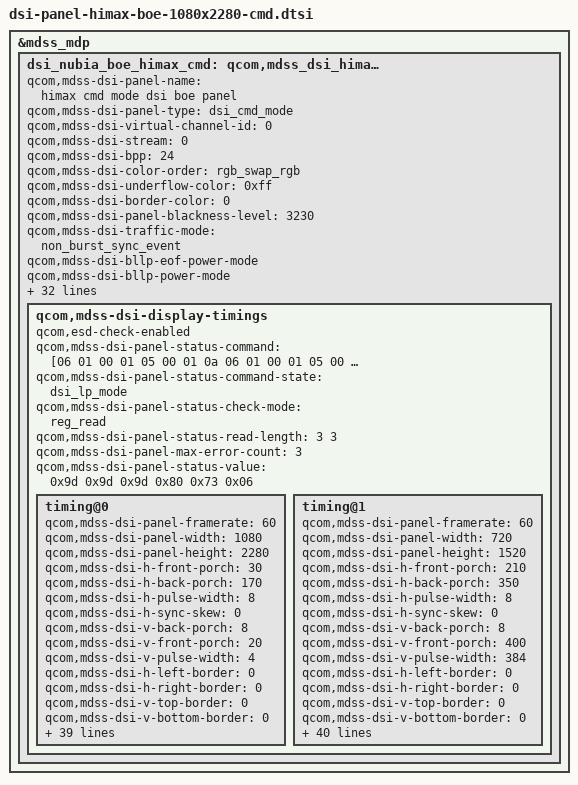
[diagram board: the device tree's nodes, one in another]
/* Copyright (c) 2016-2017, The Linux Foundation. All rights reserved.
 *
 * This program is free software; you can redistribute it and/or modify
 * it under the terms of the GNU General Public License version 2 and
 * only version 2 as published by the Free Software Foundation.
 *
 * This program is distributed in the hope that it will be useful,
 * but WITHOUT ANY WARRANTY; without even the implied warranty of
 * MERCHANTABILITY or FITNESS FOR A PARTICULAR PURPOSE.  See the
 * GNU General Public License for more details.
 */
&mdss_mdp {
	dsi_nubia_boe_himax_cmd: qcom,mdss_dsi_himax_cmd_boe {
		qcom,mdss-dsi-panel-name =
			"himax cmd mode dsi boe panel";
		qcom,mdss-dsi-panel-type = "dsi_cmd_mode";
		qcom,mdss-dsi-virtual-channel-id = <0>;
		qcom,mdss-dsi-stream = <0>;
		qcom,mdss-dsi-bpp = <24>;
		qcom,mdss-dsi-color-order = "rgb_swap_rgb";
		qcom,mdss-dsi-underflow-color = <0xff>;
		qcom,mdss-dsi-border-color = <0>;
		qcom,mdss-dsi-panel-blackness-level = <3230>;
		qcom,mdss-dsi-traffic-mode = "non_burst_sync_event";
		qcom,mdss-dsi-bllp-eof-power-mode;
		qcom,mdss-dsi-bllp-power-mode;
		qcom,mdss-dsi-lane-0-state;
		qcom,mdss-dsi-lane-1-state;
		qcom,mdss-dsi-lane-2-state;
		qcom,mdss-dsi-lane-3-state;
		qcom,mdss-dsi-dma-trigger = "trigger_sw";
		qcom,mdss-dsi-mdp-trigger = "none";
		qcom,mdss-dsi-reset-sequence =<1 2>, <0 2>, <1 60>;
		qcom,adjust-timer-wakeup-ms = <1>;
		qcom,mdss-dsi-te-pin-select = <1>;
		qcom,mdss-dsi-wr-mem-start = <0x2c>;
		qcom,mdss-dsi-wr-mem-continue = <0x3c>;
		qcom,mdss-dsi-te-dcs-command = <1>;
		qcom,mdss-dsi-te-check-enable;
		qcom,mdss-dsi-te-using-te-pin;
        qcom,mdss-dsi-t-clk-post = <0x0f>;
        qcom,mdss-dsi-t-clk-pre = <0x36>;
/**************************ESD check*******************************/
		qcom,esd-check-enabled;
		qcom,mdss-dsi-panel-status-command = [06 01 00 01 05 00 01 0a
												06 01 00 01 05 00 01 09];
		//qcom,mdss-dsi-panel-status-command = [14 01 00 01 05 00 01 0A];
		qcom,mdss-dsi-panel-status-command-state = "dsi_lp_mode";
		qcom,mdss-dsi-panel-status-check-mode = "reg_read";
		qcom,mdss-dsi-panel-status-read-length = <3 3>;
		qcom,mdss-dsi-panel-max-error-count = <3>;
		qcom,mdss-dsi-panel-status-value = <0x9d 0x9d 0x9d 0x80 0x73 0x06>;
/*********************************************************/
/************************switch panel mode*****************************/
               qcom,dynamic-mode-switch-enabled;
               qcom,dynamic-mode-switch-type="dynamic-resolution-switch-immediate";
              qcom,mdss-dsi-timing-switch-command-state="dsi_lp_mode";
/*****************************************************/
		qcom,mdss-dsi-display-timings {
/**************************ESD check*******************************/
		qcom,esd-check-enabled;
		qcom,mdss-dsi-panel-status-command = [06 01 00 01 05 00 01 0a
												06 01 00 01 05 00 01 09];
		//qcom,mdss-dsi-panel-status-command = [14 01 00 01 05 00 01 0A];
		qcom,mdss-dsi-panel-status-command-state = "dsi_lp_mode";
		qcom,mdss-dsi-panel-status-check-mode = "reg_read";
		qcom,mdss-dsi-panel-status-read-length = <3 3>;
		qcom,mdss-dsi-panel-max-error-count = <3>;
		qcom,mdss-dsi-panel-status-value = <0x9d 0x9d 0x9d 0x80 0x73 0x06>;
/*********************************************************/
			timing@0{
				qcom,mdss-dsi-panel-framerate = <60>;
				qcom,mdss-dsi-panel-width = <1080>;
				qcom,mdss-dsi-panel-height = <2280>;
				qcom,mdss-dsi-h-front-porch = <30>;
				qcom,mdss-dsi-h-back-porch = <170>;
				qcom,mdss-dsi-h-pulse-width = <8>;
				qcom,mdss-dsi-h-sync-skew = <0>;
				qcom,mdss-dsi-v-back-porch = <8>;
				qcom,mdss-dsi-v-front-porch = <20>;
				qcom,mdss-dsi-v-pulse-width = <4>;
				qcom,mdss-dsi-h-left-border = <0>;
				qcom,mdss-dsi-h-right-border = <0>;
				qcom,mdss-dsi-v-top-border = <0>;
				qcom,mdss-dsi-v-bottom-border = <0>;
				qcom,mdss-dsi-panel-jitter = <0x2 0xa>;
				qcom,mdss-dsi-on-command= [
					39 00 00 00 00 00 03 51 0f ff
					39 01 00 00 00 00 02 53 24
					05 01 00 00 00 00 01 35					
					39 00 00 00 00 00 04 B9 83 11 2E
					39 00 00 00 00 00 02 BD 00
					39 00 00 00 00 00 02 E3 09
					05 01 00 00 50 00 01 11 
					05 01 00 00 05 00 01 29 ];
				qcom,mdss-dsi-off-command = [
				05 01 00 00 28 00 01 28
				05 01 00 00 78 00 01 10];
                qcom,mdss-dsi-panel-phy-timings = [00 24 09 09 26 24 09 09 06 02 04 00];
                qcom,display-topology = <1 0 1>;
                qcom,default-topology-index = <0>;
				qcom,mdss-dsi-on-command-state = "dsi_lp_mode";
				qcom,mdss-dsi-off-command-state = "dsi_hs_mode";
				qcom,mdss-dsi-h-sync-pulse = <0>;
				qcom,mdss-dsi-lp11-init;
				qcom,mdss-dsi-init-delay-us=<30000>;
				qcom,mdss-dsi-timing-switch-command=[
					39 00 00 00 00 00 03 51 0f ff
					39 01 00 00 00 00 02 53 24
					05 01 00 00 00 00 01 35 
					39 00 00 00 00 00 04 B9 83 11 2E
					39 00 00 00 00 00 02 BD 00
					39 00 00 00 00 00 02 E3 09
					05 01 00 00 50 00 01 11 
					05 01 00 00 05 00 01 29 ];
/**************************ESD check*******************************/
		qcom,esd-check-enabled;
		qcom,mdss-dsi-panel-status-command = [06 01 00 01 05 00 01 0a
		                                      06 01 00 01 05 00 01 09];
		//qcom,mdss-dsi-panel-status-command = [14 01 00 01 05 00 01 0A];
		qcom,mdss-dsi-panel-status-command-state = "dsi_lp_mode";
		qcom,mdss-dsi-panel-status-check-mode = "reg_read";
		qcom,mdss-dsi-panel-status-read-length = <3 3>;
		qcom,mdss-dsi-panel-max-error-count = <3>;
		qcom,mdss-dsi-panel-status-value = <0x9d 0x9d 0x9d 0x80 0x73 0x06>;
/*********************************************************/
/*****************************************CABC setup start******************************/
/*					nuiba,mdss-dsi-cabc-command-cabc-off = [
											39 00 00 00 00 00 02 53 24
											39 01 00 00 00 00 02 55 00];
					nuiba,mdss-dsi-cabc-command-cabc-level1 = [
											39 00 00 00 00 00 02 53 2c
						        39 01 00 00 00 00 02 55 01];
			       		nuiba,mdss-dsi-cabc-command-cabc-off-state = "dsi_hs_mode";
					nuiba,mdss-dsi-cabc-command-cabc-level1-state = "dsi_hs_mode";
*/
/*****************************************CABC setup end******************************/
/**************************rgbw mode switch start *********************************************/
					nuiba,mdss-dsi-prim-panel-command-rgbw-normal = [
						39 00 00 00 00 00 02 53 2c
						39 00 00 00 00 00 02 55 01
						39 00 00 00 00 00 04 B9 83 11 2E
						39 00 00 00 00 00 02 BD 01
						39 00 00 00 00 00 02 C4 FF
						39 00 00 00 00 00 02 BD 02
						39 00 00 00 00 00 1B DF 87 0E 00 00 1F 95 D6 A2 82 22 01 00 00 00 00 00 40 2E 40 2E 40 40 2E 40 2E 01
						39 00 00 00 00 00 02 BD 03
						39 00 00 00 00 00 32 DF 20 20 20 7F 7F 20 B4 3D 2D B1 A5 92 C0 0C 00 7F 00 7F 00 00 00 00 10 7E 7D 08 7F 82 6C 0B 50 04 96 0C 00 80 00 00 96 70 14 00 00 3C 00 70 05 40 04
						39 00 00 00 00 00 02 BD 00
						39 00 00 00 00 00 02 E3 09
						39 01 00 00 00 00 15 EF 7F 02 7F 7F 02 00 00 80 80 FC 5E FD 75 00 FE 80 FF 80 40 E2
						/**below for read & wirte**/
						39 00 00 00 00 00 02 BD 01
						39 00 00 00 00 00 02 C4 00
						39 01 00 00 00 00 02 BD 00
					];
					nuiba,mdss-dsi-prim-panel-command-rgbw-bright = [
						39 00 00 00 00 00 02 53 2c
						39 00 00 00 00 00 02 55 01
						39 00 00 00 00 00 04 B9 83 11 2E
						39 00 00 00 00 00 02 BD 01
						39 00 00 00 00 00 02 C4 FF
						39 00 00 00 00 00 02 BD 02
						39 00 00 00 00 00 1B DF 87 0E 0A 00 1F 95 D6 A2 82 22 41 00 00 00 00 00 40 2E 40 2E 40 40 2E 40 2E 00
						39 00 00 00 00 00 02 BD 03
						39 00 00 00 00 00 32 DF 20 20 20 7F 7F 20 B4 3D 2D B1 A5 92 C0 0C 00 7F 00 7F 00 00 00 00 10 7E 7D 08 7F 82 FC 0B 00 00 96 0C 00 80 19 FE 80 70 14 FF FF 3C 99 70 05 40 00
						39 00 00 00 00 00 02 BD 00
						39 00 00 00 00 00 02 E3 09
						39 01 00 00 00 00 15 EF 10 10 7F 7F FF 00 00 80 80 FC 5E FD 75 00 FE 80 FF 80 40 22
						/**below for read & wirte**/
						39 00 00 00 00 00 02 BD 01
						39 00 00 00 00 00 02 C4 00
						39 01 00 00 00 00 02 BD 00
					];
			       nuiba,mdss-dsi-prim-panel-command-rgbw-outdoor = [
						39 00 00 00 00 00 02 53 2c
						39 00 00 00 00 00 02 55 01
						39 00 00 00 00 00 04 B9 83 11 2E
						39 00 00 00 00 00 02 BD 01
						39 00 00 00 00 00 02 C4 FF
						39 00 00 00 00 00 02 BD 03
						39 00 00 00 FF 00 32 DF 20 20 20 7F 7F 20 B4 3D 2D B1 A5 92 C0 0C 00 7F 00 7F 00 00 00 00 10 7E 7D 08 7F 82 FC 0B 00 00 96 0C 00 80 66 FE 80 70 14 FF FF 3C E6 70 05 40 00
						39 00 00 00 00 00 02 BD 01
						39 00 00 00 00 00 02 C4 00
						39 01 00 00 00 00 02 BD 00
					];

					nuiba,mdss-dsi-prim-panel-command-rgbw-normal-state = "dsi_hs_mode";
					nuiba,mdss-dsi-prim-panel-command-rgbw-bright-state = "dsi_hs_mode";
					nuiba,mdss-dsi-prim-panel-command-rgbw-outdoor-state = "dsi_hs_mode";

/**************************rgbw mode switch end*********************************************/
			};
			timing@1{
               qcom,mdss-dsi-panel-framerate = <60>;
			                    qcom,mdss-dsi-panel-width = <720>;
			                 qcom,mdss-dsi-panel-height = <1520>;
				                   qcom,mdss-dsi-h-front-porch = <210>;
				                    qcom,mdss-dsi-h-back-porch = <350>;
				                     qcom,mdss-dsi-h-pulse-width = <8>;
					               qcom,mdss-dsi-h-sync-skew = <0>;
					              qcom,mdss-dsi-v-back-porch = <8>;
					                 qcom,mdss-dsi-v-front-porch = <400>;
					                qcom,mdss-dsi-v-pulse-width = <384>;
					                qcom,mdss-dsi-h-left-border = <0>;
					                qcom,mdss-dsi-h-right-border = <0>;
					                 qcom,mdss-dsi-v-top-border = <0>;
					                qcom,mdss-dsi-v-bottom-border = <0>;
					                 qcom,mdss-dsi-panel-jitter = <0x2 0xa>;
				qcom,mdss-dsi-on-command = [
 39 01 00 00 00 00 02 FE 40 
 39 01 00 00 00 00 02 05 08 
 39 01 00 00 00 00 02 06 08 
 39 01 00 00 00 00 02 08 08 
 39 01 00 00 00 00 02 09 08 
 39 01 00 00 00 00 02 0A E0 
 39 01 00 00 00 00 02 0B CC 
 39 01 00 00 00 00 02 0C E0 
 39 01 00 00 00 00 02 0D A0 
 39 01 00 00 00 00 02 0F 5F 
 39 01 00 00 00 00 02 64 02 
 39 01 00 00 00 00 02 FE 60 
 39 01 00 00 00 00 02 00 84 
 39 01 00 00 00 00 02 01 00 
 39 01 00 00 00 00 02 02 02 
 39 01 00 00 00 00 02 03 01 
 39 01 00 00 00 00 02 04 00 
 39 01 00 00 00 00 02 05 02 
 39 01 00 00 00 00 02 06 73 
 39 01 00 00 00 00 02 07 1A 
 39 01 00 00 00 00 02 09 D4 
 39 01 00 00 00 00 02 0A 00 
 39 01 00 00 00 00 02 0B 02 
 39 01 00 00 00 00 02 0C 00 
 39 01 00 00 00 00 02 0D 00 
 39 01 00 00 00 00 02 0E 03 
 39 01 00 00 00 00 02 0F 9A 
 39 01 00 00 00 00 02 10 0A 
 39 01 00 00 00 00 02 12 D4 
 39 01 00 00 00 00 02 13 00 
 39 01 00 00 00 00 02 14 02 
 39 01 00 00 00 00 02 15 00 
 39 01 00 00 00 00 02 16 00 
 39 01 00 00 00 00 02 17 04 
 39 01 00 00 00 00 02 18 9A 
 39 01 00 00 00 00 02 19 0A 
 39 01 00 00 00 00 02 1B C4 
 39 01 00 00 00 00 02 1C 00 
 39 01 00 00 00 00 02 1D 04 
 39 01 00 00 00 00 02 1E 02 
 39 01 00 00 00 00 02 1F 00 
 39 01 00 00 00 00 02 20 06 
 39 01 00 00 00 00 02 21 1A 
 39 01 00 00 00 00 02 22 00 
 39 01 00 00 00 00 02 24 C4 
 39 01 00 00 00 00 02 25 00 
 39 01 00 00 00 00 02 26 04 
 39 01 00 00 00 00 02 27 02 
 39 01 00 00 00 00 02 28 00 
 39 01 00 00 00 00 02 29 04 
 39 01 00 00 00 00 02 2A 1A 
 39 01 00 00 00 00 02 2B 00 
 39 01 00 00 00 00 02 83 DA 
 39 01 00 00 00 00 02 84 01 
 39 01 00 00 00 00 02 85 80 
 39 01 00 00 00 00 02 86 4C 
 39 01 00 00 00 00 02 87 00 
 39 01 00 00 00 00 02 88 04 
 39 01 00 00 00 00 02 89 25 
 39 01 00 00 00 00 02 8A 6F 
 39 01 00 00 00 00 02 8B 00 
 39 01 00 00 00 00 02 FE 40 
 39 01 00 00 00 00 02 93 00 
 39 01 00 00 00 00 02 85 07 
 39 01 00 00 00 00 02 84 01 
 39 01 00 00 00 00 02 86 0A 
 39 01 00 00 00 00 02 87 00 
 39 01 00 00 00 00 02 8C 00 
 39 01 00 00 00 00 02 88 3A 
 39 01 00 00 00 00 02 89 3A 
 39 01 00 00 00 00 02 8B 0B 
 39 01 00 00 00 00 02 95 00 
 39 01 00 00 00 00 02 91 00 
 39 01 00 00 00 00 02 90 00 
 39 01 00 00 00 00 02 FE A0 
 39 01 00 00 00 00 02 13 00 
 39 01 00 00 00 00 02 33 00 
 39 01 00 00 00 00 02 FE 60 
 39 01 00 00 00 00 02 C7 03 
 39 01 00 00 00 00 02 C8 04 
 39 01 00 00 00 00 02 C9 0E 
 39 01 00 00 00 00 02 CA 01 
 39 01 00 00 00 00 02 CB 02 
 39 01 00 00 00 00 02 CC 00 
 39 01 00 00 00 00 02 CD 16 
 39 01 00 00 00 00 02 CE 17 
 39 01 00 00 00 00 02 CF 1F 
 39 01 00 00 00 00 02 D0 1F 
 39 01 00 00 00 00 02 D1 1F 
 39 01 00 00 00 00 02 D2 1F 
 39 01 00 00 00 00 02 D3 1F 
 39 01 00 00 00 00 02 D4 1F 
 39 01 00 00 00 00 02 D5 1F 
 39 01 00 00 00 00 02 D6 1F 
 39 01 00 00 00 00 02 D7 1F 
 39 01 00 00 00 00 02 D8 1F 
 39 01 00 00 00 00 02 D9 1F 
 39 01 00 00 00 00 02 DA 1F 
 39 01 00 00 00 00 02 DB 03 
 39 01 00 00 00 00 02 DC 04 
 39 01 00 00 00 00 02 DD 0E 
 39 01 00 00 00 00 02 DE 01 
 39 01 00 00 00 00 02 DF 02 
 39 01 00 00 00 00 02 E0 00 
 39 01 00 00 00 00 02 E1 16 
 39 01 00 00 00 00 02 E2 17 
 39 01 00 00 00 00 02 E3 1F 
 39 01 00 00 00 00 02 E4 1F 
 39 01 00 00 00 00 02 E5 1F 
 39 01 00 00 00 00 02 E6 1F 
 39 01 00 00 00 00 02 E7 1F 
 39 01 00 00 00 00 02 E8 1F 
 39 01 00 00 00 00 02 E9 1F 
 39 01 00 00 00 00 02 EA 1F 
 39 01 00 00 00 00 02 EB 1F 
 39 01 00 00 00 00 02 EC 1F 
 39 01 00 00 00 00 02 ED 1F 
 39 01 00 00 00 00 02 EE 1F 
 39 01 00 00 00 00 02 EF 03 
 39 01 00 00 00 00 02 FE 90 
 39 01 00 00 00 00 02 AF 80 
 39 01 00 00 00 00 02 B0 02 
 39 01 00 00 00 00 02 B1 49 
 39 01 00 00 00 00 02 B2 04 
 39 01 00 00 00 00 02 B3 92 
 39 01 00 00 00 00 02 B4 0B 
 39 01 00 00 00 00 02 B5 6D 
 39 01 00 00 00 00 02 B6 00 
 39 01 00 00 00 00 02 B7 00 
 39 01 00 00 00 00 02 B8 06 
 39 01 00 00 00 00 02 B9 DB 
 39 01 00 00 00 00 02 BA 09 
 39 01 00 00 00 00 02 BB 24 
 39 01 00 00 00 00 02 BC 02 
 39 01 00 00 00 00 02 BD 49 
 39 01 00 00 00 00 02 BE 04 
 39 01 00 00 00 00 02 BF 92 
 39 01 00 00 00 00 02 C0 0B 
 39 01 00 00 00 00 02 C1 6D 
 39 01 00 00 00 00 02 C2 00 
 39 01 00 00 00 00 02 C3 00 
 39 01 00 00 00 00 02 C4 06 
 39 01 00 00 00 00 02 C5 DB 
 39 01 00 00 00 00 02 C6 09 
 39 01 00 00 00 00 02 C7 24 
 39 01 00 00 00 00 02 FE 70 
 39 01 00 00 00 00 02 5A 18 
 39 01 00 00 00 00 02 5C 00 
 39 01 00 00 00 00 02 5D 4C 
 39 01 00 00 00 00 02 A9 35 
 39 01 00 00 00 00 02 CB 06
 39 01 00 00 00 00 02 FE 40 
 39 01 00 00 00 00 02 4E 07 
 39 01 00 00 00 00 02 4D 23
 39 01 00 00 00 00 02 4F 80 
 39 01 00 00 00 00 02 FE D0 
 39 01 00 00 00 00 02 71 03 
 39 01 00 00 00 00 02 06 0F 
 39 01 00 00 00 00 02 4B F0 
 39 01 00 00 00 00 02 07 8E 
 39 01 00 00 00 00 02 FE 50 
 39 01 00 00 00 00 02 DA 01 
 39 01 00 00 00 00 02 FE 52 
 39 01 00 00 00 00 02 DA 01 
 39 01 00 00 00 00 02 FE A0 
 39 01 00 00 00 00 02 04 80 
 39 01 00 00 00 00 02 2A 1A 
 39 01 00 00 00 00 02 2B 17 
 39 01 00 00 00 00 02 2F 35 
 39 01 00 00 00 00 02 26 10 
 39 01 00 00 00 00 02 31 88 
 39 01 00 00 00 00 02 32 88 
 39 01 00 00 00 00 02 33 00  
 39 01 00 00 00 00 02 36 1E 
 39 01 00 00 00 00 02 37 91 
 39 01 00 00 00 00 02 0B 33 
 39 01 00 00 00 00 02 FE 70 
 39 01 00 00 00 00 02 49 05 
 39 01 00 00 00 00 02 4A 2E 
 39 01 00 00 00 00 02 4B 58 
 39 01 00 00 00 00 02 4C 77 
 39 01 00 00 00 00 02 4D A1 
 39 01 00 00 00 00 02 4E DE 
 39 01 00 00 00 00 02 4F 2C 
 39 01 00 00 00 00 02 50 97 
 39 01 00 00 00 00 02 51 2A 
 39 01 00 00 00 00 02 AD EC 
 39 01 00 00 00 00 02 AE 80 
 39 01 00 00 00 00 02 AF 00 
 39 01 00 00 00 00 02 B0 50 
 39 01 00 00 00 00 02 B1 3A 
 39 01 00 00 00 00 02 FE 70 
 39 01 00 00 00 00 02 48 05 
 39 01 00 00 00 00 02 7E 4A 
 39 01 00 00 00 00 02 B2 00 
 39 01 00 00 00 00 02 B3 01 
 39 01 00 00 00 00 02 B4 02 
 39 01 00 00 00 00 02 B5 06 
 39 01 00 00 00 00 02 B6 08 
 39 01 00 00 00 00 02 B7 10 
 39 01 00 00 00 00 02 B8 28 
 39 01 00 00 00 00 02 B9 61 
 39 01 00 00 00 00 02 BA AF 
 39 01 00 00 00 00 02 BB 90 
 39 01 00 00 00 00 02 BC A8 
 39 01 00 00 00 00 02 BD 00 
 39 01 00 00 00 00 02 BE 00 
 39 01 00 00 00 00 02 BF 24 
 39 01 00 00 00 00 02 FE 70
 39 01 00 00 00 00 02 7D 32
 39 01 00 00 00 00 02 7F 80
 39 01 00 00 00 00 02 8E FF 
 39 01 00 00 00 00 02 8F FF 
 39 01 00 00 00 00 02 90 3B 
 39 01 00 00 00 00 02 91 3B 
 39 01 00 00 00 00 02 92 3B 
 39 01 00 00 00 00 02 93 3B 
 39 01 00 00 00 00 02 94 3B
 39 01 00 00 00 00 02 99 02
 39 01 00 00 00 00 02 DF 33
 39 01 00 00 00 00 02 E0 9A
 39 01 00 00 00 00 02 E1 33
 39 01 00 00 00 00 02 9A 51
 39 01 00 00 00 00 02 FE 00 
 39 01 00 00 00 00 02 C2 08 
 39 01 00 00 00 00 02 35 00 
 39 01 00 00 00 00 03 51 00 00
 29 01 00 00 32 00 02 11 00
 29 01 00 00 32 00 02 29 00
];
				qcom,mdss-dsi-off-command = [
				05 01 00 00 28 00 01 28
				05 01 00 00 78 00 01 10];				
                qcom,mdss-dsi-panel-phy-timings = [00 24 09 09 26 24 09 09 06 02 04 00];
				qcom,display-topology = <1 0 1>;
				qcom,default-topology-index = <0>;
				qcom,mdss-dsi-on-command-state = "dsi_lp_mode";
				qcom,mdss-dsi-off-command-state = "dsi_hs_mode";
				qcom,mdss-dsi-h-sync-pulse = <0>;
				qcom,mdss-dsi-lp11-init;
				qcom,mdss-dsi-init-delay-us=<30000>;
				qcom,mdss-dsi-timing-switch-command=[
 39 01 00 00 00 00 02 FE 40 
 39 01 00 00 00 00 02 05 08 
 39 01 00 00 00 00 02 06 08 
 39 01 00 00 00 00 02 08 08 
 39 01 00 00 00 00 02 09 08 
 39 01 00 00 00 00 02 0A E0 
 39 01 00 00 00 00 02 0B CC 
 39 01 00 00 00 00 02 0C E0 
 39 01 00 00 00 00 02 0D A0 
 39 01 00 00 00 00 02 0F 5F 
 39 01 00 00 00 00 02 64 02 
 39 01 00 00 00 00 02 FE 60 
 39 01 00 00 00 00 02 00 84 
 39 01 00 00 00 00 02 01 00 
 39 01 00 00 00 00 02 02 02 
 39 01 00 00 00 00 02 03 01 
 39 01 00 00 00 00 02 04 00 
 39 01 00 00 00 00 02 05 02 
 39 01 00 00 00 00 02 06 73 
 39 01 00 00 00 00 02 07 1A 
 39 01 00 00 00 00 02 09 D4 
 39 01 00 00 00 00 02 0A 00 
 39 01 00 00 00 00 02 0B 02 
 39 01 00 00 00 00 02 0C 00 
 39 01 00 00 00 00 02 0D 00 
 39 01 00 00 00 00 02 0E 03 
 39 01 00 00 00 00 02 0F 9A 
 39 01 00 00 00 00 02 10 0A 
 39 01 00 00 00 00 02 12 D4 
 39 01 00 00 00 00 02 13 00 
 39 01 00 00 00 00 02 14 02 
 39 01 00 00 00 00 02 15 00 
 39 01 00 00 00 00 02 16 00 
 39 01 00 00 00 00 02 17 04 
 39 01 00 00 00 00 02 18 9A 
 39 01 00 00 00 00 02 19 0A 
 39 01 00 00 00 00 02 1B C4 
 39 01 00 00 00 00 02 1C 00 
 39 01 00 00 00 00 02 1D 04 
 39 01 00 00 00 00 02 1E 02 
 39 01 00 00 00 00 02 1F 00 
 39 01 00 00 00 00 02 20 06 
 39 01 00 00 00 00 02 21 1A 
 39 01 00 00 00 00 02 22 00 
 39 01 00 00 00 00 02 24 C4 
 39 01 00 00 00 00 02 25 00 
 39 01 00 00 00 00 02 26 04 
 39 01 00 00 00 00 02 27 02 
 39 01 00 00 00 00 02 28 00 
 39 01 00 00 00 00 02 29 04 
 39 01 00 00 00 00 02 2A 1A 
 39 01 00 00 00 00 02 2B 00 
 39 01 00 00 00 00 02 83 DA 
 39 01 00 00 00 00 02 84 01 
 39 01 00 00 00 00 02 85 80 
 39 01 00 00 00 00 02 86 4C 
 39 01 00 00 00 00 02 87 00 
 39 01 00 00 00 00 02 88 04 
 39 01 00 00 00 00 02 89 25 
 39 01 00 00 00 00 02 8A 6F 
 39 01 00 00 00 00 02 8B 00 
 39 01 00 00 00 00 02 FE 40 
 39 01 00 00 00 00 02 93 00 
 39 01 00 00 00 00 02 85 07 
 39 01 00 00 00 00 02 84 01 
 39 01 00 00 00 00 02 86 0A 
 39 01 00 00 00 00 02 87 00 
 39 01 00 00 00 00 02 8C 00 
 39 01 00 00 00 00 02 88 3A 
 39 01 00 00 00 00 02 89 3A 
 39 01 00 00 00 00 02 8B 0B 
 39 01 00 00 00 00 02 95 00 
 39 01 00 00 00 00 02 91 00 
 39 01 00 00 00 00 02 90 00 
 39 01 00 00 00 00 02 FE A0 
 39 01 00 00 00 00 02 13 00 
 39 01 00 00 00 00 02 33 00 
 39 01 00 00 00 00 02 FE 60 
 39 01 00 00 00 00 02 C7 03 
 39 01 00 00 00 00 02 C8 04 
 39 01 00 00 00 00 02 C9 0E 
 39 01 00 00 00 00 02 CA 01 
 39 01 00 00 00 00 02 CB 02 
 39 01 00 00 00 00 02 CC 00 
 39 01 00 00 00 00 02 CD 16 
 39 01 00 00 00 00 02 CE 17 
 39 01 00 00 00 00 02 CF 1F 
 39 01 00 00 00 00 02 D0 1F 
 39 01 00 00 00 00 02 D1 1F 
 39 01 00 00 00 00 02 D2 1F 
 39 01 00 00 00 00 02 D3 1F 
 39 01 00 00 00 00 02 D4 1F 
 39 01 00 00 00 00 02 D5 1F 
 39 01 00 00 00 00 02 D6 1F 
 39 01 00 00 00 00 02 D7 1F 
 39 01 00 00 00 00 02 D8 1F 
 39 01 00 00 00 00 02 D9 1F 
 39 01 00 00 00 00 02 DA 1F 
 39 01 00 00 00 00 02 DB 03 
 39 01 00 00 00 00 02 DC 04 
 39 01 00 00 00 00 02 DD 0E 
 39 01 00 00 00 00 02 DE 01 
 39 01 00 00 00 00 02 DF 02 
 39 01 00 00 00 00 02 E0 00 
 39 01 00 00 00 00 02 E1 16 
 39 01 00 00 00 00 02 E2 17 
 39 01 00 00 00 00 02 E3 1F 
 39 01 00 00 00 00 02 E4 1F 
 39 01 00 00 00 00 02 E5 1F 
 39 01 00 00 00 00 02 E6 1F 
 39 01 00 00 00 00 02 E7 1F 
 39 01 00 00 00 00 02 E8 1F 
 39 01 00 00 00 00 02 E9 1F 
 39 01 00 00 00 00 02 EA 1F 
 39 01 00 00 00 00 02 EB 1F 
 39 01 00 00 00 00 02 EC 1F 
 39 01 00 00 00 00 02 ED 1F 
 39 01 00 00 00 00 02 EE 1F 
 39 01 00 00 00 00 02 EF 03 
 39 01 00 00 00 00 02 FE 90 
 39 01 00 00 00 00 02 AF 80 
 39 01 00 00 00 00 02 B0 02 
 39 01 00 00 00 00 02 B1 49 
 39 01 00 00 00 00 02 B2 04 
 39 01 00 00 00 00 02 B3 92 
 39 01 00 00 00 00 02 B4 0B 
 39 01 00 00 00 00 02 B5 6D 
 39 01 00 00 00 00 02 B6 00 
 39 01 00 00 00 00 02 B7 00 
 39 01 00 00 00 00 02 B8 06 
 39 01 00 00 00 00 02 B9 DB 
 39 01 00 00 00 00 02 BA 09 
 39 01 00 00 00 00 02 BB 24 
 39 01 00 00 00 00 02 BC 02 
 39 01 00 00 00 00 02 BD 49 
 39 01 00 00 00 00 02 BE 04 
 39 01 00 00 00 00 02 BF 92 
 39 01 00 00 00 00 02 C0 0B 
 39 01 00 00 00 00 02 C1 6D 
 39 01 00 00 00 00 02 C2 00 
 39 01 00 00 00 00 02 C3 00 
 39 01 00 00 00 00 02 C4 06 
 39 01 00 00 00 00 02 C5 DB 
 39 01 00 00 00 00 02 C6 09 
 39 01 00 00 00 00 02 C7 24 
 39 01 00 00 00 00 02 FE 70 
 39 01 00 00 00 00 02 5A 18 
 39 01 00 00 00 00 02 5C 00 
 39 01 00 00 00 00 02 5D 4C 
 39 01 00 00 00 00 02 A9 35
 39 01 00 00 00 00 02 CB 06
 39 01 00 00 00 00 02 FE 40 
 39 01 00 00 00 00 02 4E 07 
 39 01 00 00 00 00 02 4D 23
 39 01 00 00 00 00 02 4F 80 
 39 01 00 00 00 00 02 FE D0 
 39 01 00 00 00 00 02 71 03 
 39 01 00 00 00 00 02 06 0F 
 39 01 00 00 00 00 02 4B F0 
 39 01 00 00 00 00 02 07 8E 
 39 01 00 00 00 00 02 FE 50 
 39 01 00 00 00 00 02 DA 01 
 39 01 00 00 00 00 02 FE 52 
 39 01 00 00 00 00 02 DA 01 
 39 01 00 00 00 00 02 FE A0 
 39 01 00 00 00 00 02 04 80 
 39 01 00 00 00 00 02 2A 1A 
 39 01 00 00 00 00 02 2B 17 
 39 01 00 00 00 00 02 2F 35 
 39 01 00 00 00 00 02 26 10 
 39 01 00 00 00 00 02 31 88 
 39 01 00 00 00 00 02 32 88 
 39 01 00 00 00 00 02 33 00  
 39 01 00 00 00 00 02 36 1E 
 39 01 00 00 00 00 02 37 91 
 39 01 00 00 00 00 02 0B 33 
 39 01 00 00 00 00 02 FE 70 
 39 01 00 00 00 00 02 49 05 
 39 01 00 00 00 00 02 4A 2E 
 39 01 00 00 00 00 02 4B 58 
 39 01 00 00 00 00 02 4C 77 
 39 01 00 00 00 00 02 4D A1 
 39 01 00 00 00 00 02 4E DE 
 39 01 00 00 00 00 02 4F 2C 
 39 01 00 00 00 00 02 50 97 
 39 01 00 00 00 00 02 51 2A 
 39 01 00 00 00 00 02 AD EC 
 39 01 00 00 00 00 02 AE 80 
 39 01 00 00 00 00 02 AF 00 
 39 01 00 00 00 00 02 B0 50 
 39 01 00 00 00 00 02 B1 3A 
 39 01 00 00 00 00 02 FE 70 
 39 01 00 00 00 00 02 48 05 
 39 01 00 00 00 00 02 7E 4A 
 39 01 00 00 00 00 02 B2 00 
 39 01 00 00 00 00 02 B3 01 
 39 01 00 00 00 00 02 B4 02 
 39 01 00 00 00 00 02 B5 06 
 39 01 00 00 00 00 02 B6 08 
 39 01 00 00 00 00 02 B7 10 
 39 01 00 00 00 00 02 B8 28 
 39 01 00 00 00 00 02 B9 61 
 39 01 00 00 00 00 02 BA AF 
 39 01 00 00 00 00 02 BB 90 
 39 01 00 00 00 00 02 BC A8 
 39 01 00 00 00 00 02 BD 00 
 39 01 00 00 00 00 02 BE 00 
 39 01 00 00 00 00 02 BF 24 
 39 01 00 00 00 00 02 FE 70
 39 01 00 00 00 00 02 7D 32
 39 01 00 00 00 00 02 7F 80
 39 01 00 00 00 00 02 8E FF 
 39 01 00 00 00 00 02 8F FF 
 39 01 00 00 00 00 02 90 3B 
 39 01 00 00 00 00 02 91 3B 
 39 01 00 00 00 00 02 92 3B 
 39 01 00 00 00 00 02 93 3B 
 39 01 00 00 00 00 02 94 3B
 39 01 00 00 00 00 02 99 02
 39 01 00 00 00 00 02 DF 33
 39 01 00 00 00 00 02 E0 9A
 39 01 00 00 00 00 02 E1 33
 39 01 00 00 00 00 02 9A 51
 39 01 00 00 00 00 02 FE 00 
 39 01 00 00 00 00 02 C2 08 
 39 01 00 00 00 00 02 35 00 
 39 01 00 00 00 00 03 51 00 00
 29 01 00 00 32 00 02 11 00
 29 01 00 00 32 00 02 29 00
];
/*****************************************ACL(r55 is used for auto current limit) setup start******************************/
				nuiba,mdss-dsi-cabc-command-cabc-off = [15 01 00 00 00 00 02 55 00];
				nuiba,mdss-dsi-cabc-command-cabc-level3 = [15 01 00 00 00 00 02 55 03];
       			nuiba,mdss-dsi-cabc-command-cabc-off-state = "dsi_hs_mode";
				nuiba,mdss-dsi-cabc-command-cabc-level3-state= "dsi_hs_mode";

/*****************************************ACL setup end******************************/
/**********************************dual gamma switch start********************************************/
				nuiba,mdss-dsi-sub-lcd-gamma-high=[
				15 00 00 00 00 00 02 fe 40
				15 00 00 00 00 00 02 37 80
				15 00 00 00 00 00 02 39 b8
				15 00 00 00 00 00 02 64 00
				15 00 00 00 00 00 02 fe 70
				15 00 00 00 00 00 02 a9 35
				15 00 00 00 00 00 02 fe 00
				15 01 00 00 00 00 02 53 20];
				nuiba,mdss-dsi-sub-lcd-gamma-low=[
				15 00 00 00 00 00 02 fe 40
				15 00 00 00 00 00 02 37 c0
				15 00 00 00 00 00 02 39 08
				15 00 00 00 00 00 02 64 02
				15 00 00 00 00 00 02 fe 70
				15 00 00 00 00 00 02 a9 ed
				15 00 00 00 00 00 02 fe 00
				15 01 00 00 00 00 02 53 e0];
				nuiba,mdss-dsi-sub-lcd-gamma-low-state="dsi_hs_mode";
				nuiba,mdss-dsi-sub-lcd-gamma-high-state="dsi_hs_mode";
/**********************************dual gamma switch end********************************************/
/***************************************AOD start***************************************************/
				nuiba,mdss-dsi-sub-lcd-command-aod-on = [15 00 00 00 00 00 02 fe 40
				                                         15 00 00 00 00 00 02 38 68 
				                                         15 01 00 00 00 00 02 fe 00
														 05 01 00 00 00 00 01 39];
				nuiba,mdss-dsi-sub-lcd-command-aod-off = [15 00 00 00 00 00 02 fe 40
				                                          15 00 00 00 00 00 02 38 60
				                                          15 01 00 00 00 00 02 fe 00
														  05 01 00 00 00 00 01 38];
				nuiba,mdss-dsi-sub-lcd-command-aod-on-state = "dsi_hs_mode";
				nuiba,mdss-dsi-sub-lcd-command-aod-off-state = "dsi_hs_mode";
/***************************************AOD end***************************************************/
			};
		};
	};
};
